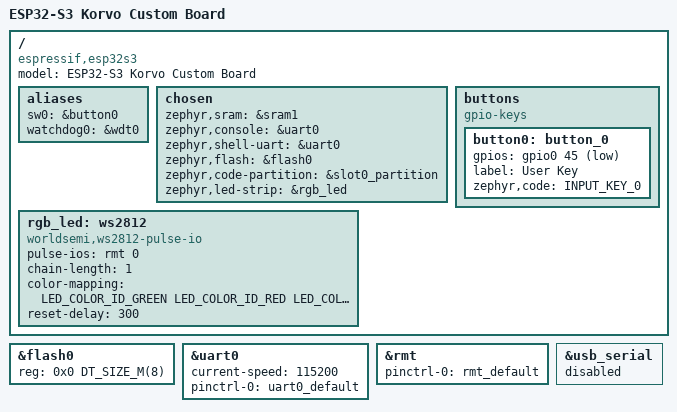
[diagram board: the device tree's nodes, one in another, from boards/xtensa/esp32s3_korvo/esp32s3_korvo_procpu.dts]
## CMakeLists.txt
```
cmake_minimum_required(VERSION 3.30.0)

find_package(Zephyr REQUIRED HINTS $ENV{ZEPHYR_BASE})
project(blinky_s3)

target_sources(app PRIVATE src/main.c)
```

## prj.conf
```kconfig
# SPDX-License-Identifier: Apache-2.0

# 板载 WS2812（IO48，走 RMT）
CONFIG_LED_STRIP=y
CONFIG_WS2812_STRIP_PULSE_IO=y

# led_strip 用不到裸 GPIO 也行，但 GPIO 是这块板的默认能力，留着方便后续实验
CONFIG_GPIO=y
```

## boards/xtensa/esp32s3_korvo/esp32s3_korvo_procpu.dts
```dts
/*
 * SPDX-License-Identifier: Apache-2.0
 *
 * 板级资源（按我们手上的板子）：
 *   - 用户按键 KEY : GPIO45，按下接地（INPUT_KEY_0）
 *   - 板载 RGB    : WS2812 一颗，数据脚 GPIO48，走 RMT
 *   - 控制台       : uart0（IO43 TX / IO44 RX，USB-Serial-JTAG）
 */

/dts-v1/;

#include <espressif/esp32s3/esp32s3.dtsi>
#include <espressif/partitions_0x0_amp.dtsi>
#include <zephyr/dt-bindings/led/led.h>
#include <zephyr/dt-bindings/input/input-event-codes.h>
#include "esp32s3_korvo-pinctrl.dtsi"

/ {
	compatible = "espressif,esp32s3";
	model = "ESP32-S3 Korvo Custom Board";

	aliases {
		sw0 = &button0;
		watchdog0 = &wdt0;
	};

	chosen {
		zephyr,sram = &sram1;
		zephyr,console = &uart0;
		zephyr,shell-uart = &uart0;
		zephyr,flash = &flash0;
		zephyr,code-partition = &slot0_partition;
		zephyr,led-strip = &rgb_led;
	};

	/* 板载 WS2812 一颗：RMT 通道 0，物理顺序 GRB */
	rgb_led: ws2812 {
		compatible = "worldsemi,ws2812-pulse-io";
		pulse-ios = <&rmt 0>;
		chain-length = <1>;
		color-mapping = <LED_COLOR_ID_GREEN
				 LED_COLOR_ID_RED
				 LED_COLOR_ID_BLUE>;
		reset-delay = <300>;
	};

	/* 用户按键 KEY：IO45，按下接地 */
	buttons {
		compatible = "gpio-keys";

		button0: button_0 {
			gpios = <&gpio0 45 (GPIO_PULL_UP | GPIO_ACTIVE_LOW)>;
			label = "User Key";
			zephyr,code = <INPUT_KEY_0>;
		};
	};
};

&flash0 {
	reg = <0x0 DT_SIZE_M(8)>;
	ranges = <0x0 0x0 DT_SIZE_M(8)>;
};

&uart0 {
	current-speed = <115200>;
	pinctrl-0 = <&uart0_default>;
	pinctrl-names = "default";
	status = "okay";
};

&rmt {
	pinctrl-0 = <&rmt_default>;
	pinctrl-names = "default";
	status = "okay";
};

&usb_serial {
	status = "disabled";
};
```

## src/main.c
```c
/*
 * SPDX-License-Identifier: Apache-2.0
 *
 * 第三课的"点灯"：板载 RGB（WS2812，数据脚 IO48）循环变色。
 *
 * 说明：Up 主第三课用的是 gpio-leds（一颗普通 LED）。我们这块板没有普通 LED，
 * 只有一颗 WS2812，所以不能套 gpio-leds——必须走 led_strip 驱动。
 * 设备由 dts 的 chosen（zephyr,led-strip）指定，代码里不写引脚号。
 */

#include <zephyr/kernel.h>
#include <zephyr/drivers/led_strip.h>

#define STRIP_NODE DT_CHOSEN(zephyr_led_strip)
static const struct device *strip = DEVICE_DT_GET(STRIP_NODE);

static const struct led_rgb colors[] = {
	{ .r = 0x20, .g = 0x00, .b = 0x00 }, /* 红 */
	{ .r = 0x00, .g = 0x20, .b = 0x00 }, /* 绿 */
	{ .r = 0x00, .g = 0x00, .b = 0x20 }, /* 蓝 */
	{ .r = 0x00, .g = 0x00, .b = 0x00 }, /* 关 */
};

int main(void)
{
	unsigned int i = 0;

	if (!device_is_ready(strip)) {
		return -1;
	}

	while (1) {
		struct led_rgb px = colors[i % ARRAY_SIZE(colors)];

		led_strip_update_rgb(strip, &px, 1);
		i++;
		k_msleep(1000);
	}

	return 0;
}
```
